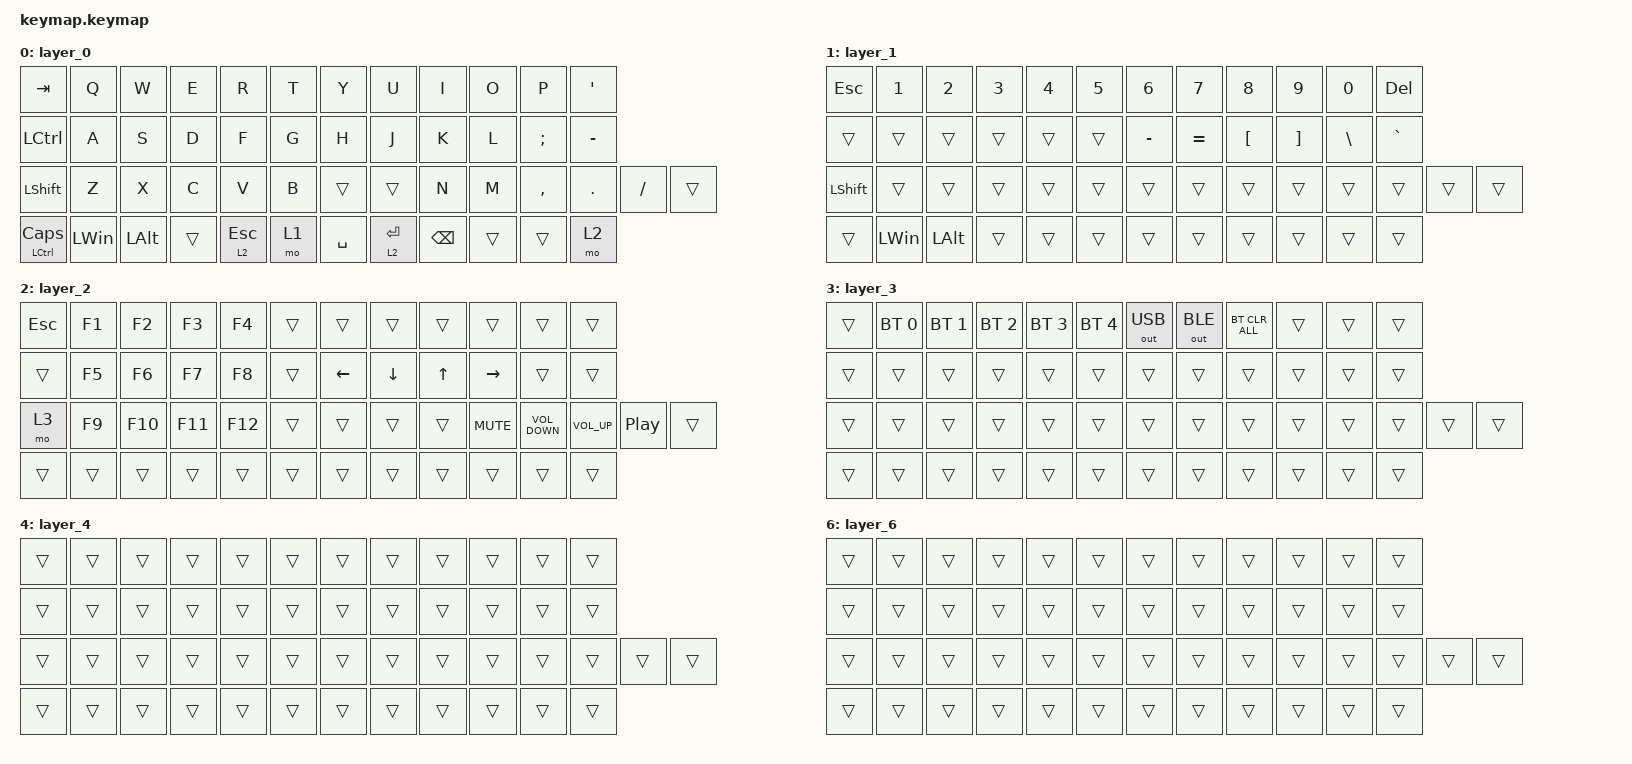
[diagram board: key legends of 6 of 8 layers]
#include <mouse-gesture.dtsi>
#include <zephyr/dt-bindings/input/input-event-codes.h>
#include <behaviors.dtsi>
#include <dt-bindings/zmk/bt.h>
#include <dt-bindings/zmk/keys.h>
#include <dt-bindings/zmk/outputs.h>
#include <dt-bindings/zmk/pointing.h>

&zip_mouse_gesture {
    stroke-size = <200>;
    enable-eager-mode;
    suppress-movement;
    gesture-cooldown-ms = <0>;

    history_back {
        pattern = <GESTURE_LEFT>;
        bindings = <&mkp MB4>;
    };

    history_forward {
        pattern = <GESTURE_RIGHT>;
        bindings = <&mkp MB5>;
    };
};

/ {
    combos {
        compatible = "zmk,combos";

        left-click {
            bindings = <&mkp MB1>;
            key-positions = <19 20>;
        };

        right-click {
            bindings = <&mkp MB2>;
            key-positions = <20 21>;
        };

        scroll-layer {
            bindings = <&mo 5>;
            key-positions = <8 21>;
        };

        sniper-layer {
            bindings = <&mo 6>;
            key-positions = <36 21>;
        };

        gesture-hold {
            bindings = <&mo 7>;
            key-positions = <8 9>;
            slow-release;
        };

        middle-click {
            bindings = <&mkp MB3>;
            key-positions = <7 8>;
        };
    };

    keymap {
        compatible = "zmk,keymap";

        layer_0 {
            bindings = <
&kp TAB             &kp Q         &kp W         &kp E   &kp R      &kp T  &kp Y      &kp U        &kp I          &kp O   &kp P          &kp SQT
&kp LCTRL           &kp A         &kp S         &kp D   &kp F      &kp G  &kp H      &kp J        &kp K          &kp L   &kp SEMICOLON  &kp MINUS
&kp LSHFT           &kp Z         &kp X         &kp C   &kp V      &kp B  &trans     &trans       &kp N          &kp M   &kp COMMA      &kp DOT    &kp SLASH  &trans
&mt LCTRL CAPSLOCK  &kp LEFT_WIN  &kp LEFT_ALT  &trans  &lt 2 ESC  &mo 1  &kp SPACE  &lt 2 ENTER  &kp BACKSPACE  &trans  &trans         &mo 2
            >;
        };

        layer_1 {
            bindings = <
&kp ESCAPE      &kp N1        &kp N2        &kp N3  &kp N4  &kp N5  &kp N6     &kp N7     &kp N8            &kp N9             &kp N0         &kp DELETE
&trans          &trans        &trans        &trans  &trans  &trans  &kp MINUS  &kp EQUAL  &kp LEFT_BRACKET  &kp RIGHT_BRACKET  &kp BACKSLASH  &kp GRAVE
&kp LEFT_SHIFT  &trans        &trans        &trans  &trans  &trans  &trans     &trans     &trans            &trans             &trans         &trans      &trans  &trans
&trans          &kp LEFT_WIN  &kp LEFT_ALT  &trans  &trans  &trans  &trans     &trans     &trans            &trans             &trans         &trans
            >;
        };

        layer_2 {
            bindings = <
&kp ESCAPE  &kp F1  &kp F2   &kp F3   &kp F4   &trans  &trans    &trans    &trans  &trans      &trans             &trans
&trans      &kp F5  &kp F6   &kp F7   &kp F8   &trans  &kp LEFT  &kp DOWN  &kp UP  &kp RIGHT   &trans             &trans
&mo 3       &kp F9  &kp F10  &kp F11  &kp F12  &trans  &trans    &trans    &trans  &kp C_MUTE  &kp C_VOLUME_DOWN  &kp C_VOLUME_UP  &kp C_PLAY_PAUSE  &trans
&trans      &trans  &trans   &trans   &trans   &trans  &trans    &trans    &trans  &trans      &trans             &trans
            >;
        };

        layer_3 {
            bindings = <
&trans  &bt BT_SEL 0  &bt BT_SEL 1  &bt BT_SEL 2  &bt BT_SEL 3  &bt BT_SEL 4  &out OUT_USB  &out OUT_BLE  &bt BT_CLR_ALL  &trans  &trans  &trans
&trans  &trans        &trans        &trans        &trans        &trans        &trans        &trans        &trans          &trans  &trans  &trans
&trans  &trans        &trans        &trans        &trans        &trans        &trans        &trans        &trans          &trans  &trans  &trans  &trans  &trans
&trans  &trans        &trans        &trans        &trans        &trans        &trans        &trans        &trans          &trans  &trans  &trans
            >;
        };

        layer_4 {
            bindings = <
&trans  &trans  &trans  &trans  &trans  &trans  &trans  &trans  &trans  &trans  &trans  &trans
&trans  &trans  &trans  &trans  &trans  &trans  &trans  &trans  &trans  &trans  &trans  &trans
&trans  &trans  &trans  &trans  &trans  &trans  &trans  &trans  &trans  &trans  &trans  &trans  &trans  &trans
&trans  &trans  &trans  &trans  &trans  &trans  &trans  &trans  &trans  &trans  &trans  &trans
            >;
        };

        layer_5 {
            bindings = <
&trans  &trans  &trans  &trans  &trans  &trans  &trans  &trans  &trans  &trans  &trans  &trans
&trans  &trans  &trans  &trans  &trans  &trans  &trans  &trans  &trans  &trans  &trans  &trans
&trans  &trans  &trans  &trans  &trans  &trans  &trans  &trans  &trans  &trans  &trans  &trans  &trans  &trans
&trans  &trans  &trans  &trans  &trans  &trans  &trans  &trans  &trans  &trans  &trans
            >;
        };

        layer_6 {
            bindings = <
&trans  &trans  &trans  &trans  &trans  &trans  &trans  &trans  &trans  &trans  &trans  &trans
&trans  &trans  &trans  &trans  &trans  &trans  &trans  &trans  &trans  &trans  &trans  &trans
&trans  &trans  &trans  &trans  &trans  &trans  &trans  &trans  &trans  &trans  &trans  &trans  &trans  &trans
&trans  &trans  &trans  &trans  &trans  &trans  &trans  &trans  &trans  &trans  &trans  &trans
            >;
        };

        layer_7 {
            bindings = <
&trans  &trans  &trans  &trans  &trans  &trans  &trans  &trans  &trans  &trans  &trans  &trans
&trans  &trans  &trans  &trans  &trans  &trans  &trans  &trans  &trans  &trans  &trans  &trans
&trans  &trans  &trans  &trans  &trans  &trans  &trans  &trans  &trans  &trans  &trans  &trans  &trans  &trans
&trans  &trans  &trans  &trans  &trans  &trans  &trans  &trans  &trans  &trans
            >;
        };
    };

    layer_listeners {
        compatible = "zmk,layer-listeners";

        mouse_gesture {
            layers = <7>;
            bindings = <&mouse_gesture_on &mouse_gesture_off>;
        };
    };
};
